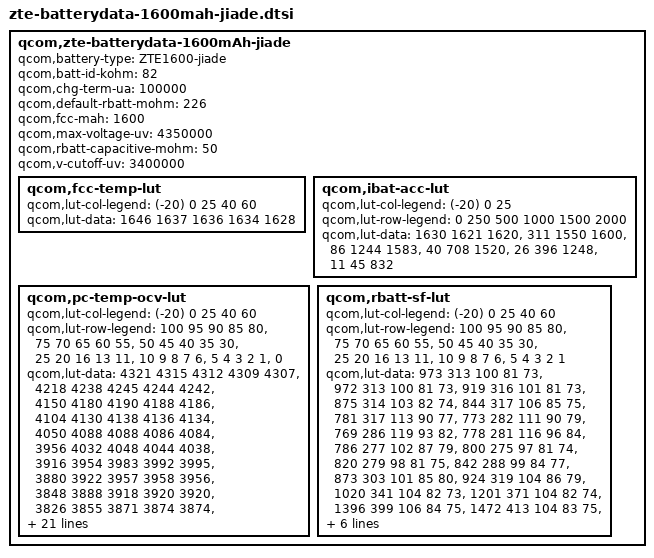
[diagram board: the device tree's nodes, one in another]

qcom,zte-batterydata-1600mAh-jiade {
	qcom,battery-type = "ZTE1600-jiade";
	qcom,batt-id-kohm = <82>;
	qcom,chg-term-ua = <100000>;
	qcom,default-rbatt-mohm = <226>;
	qcom,fcc-mah = <1600>;
	qcom,max-voltage-uv = <4350000>;
	qcom,rbatt-capacitive-mohm = <50>;
	qcom,v-cutoff-uv = <3400000>;

	qcom,fcc-temp-lut {
		qcom,lut-col-legend = <(-20) 0 25 40 60>;
		qcom,lut-data = <1646 1637 1636 1634 1628>;
	};

	qcom,ibat-acc-lut {
		qcom,lut-col-legend = <(-20) 0 25>;
		qcom,lut-row-legend = <0 250 500 1000 1500 2000>;
		qcom,lut-data = <1630 1621 1620>,
				<311 1550 1600>,
				<86 1244 1583>,
				<40 708 1520>,
				<26 396 1248>,
				<11 45 832>;
	};

	qcom,pc-temp-ocv-lut {
		qcom,lut-col-legend = <(-20) 0 25 40 60>;
		qcom,lut-row-legend = <100 95 90 85 80>,
					<75 70 65 60 55>,
					<50 45 40 35 30>,
					<25 20 16 13 11>,
					<10 9 8 7 6>,
					<5 4 3 2 1>,
					<0>;
		qcom,lut-data = <4321 4315 4312 4309 4307>,
				<4218 4238 4245 4244 4242>,
				<4150 4180 4190 4188 4186>,
				<4104 4130 4138 4136 4134>,
				<4050 4088 4088 4086 4084>,
				<3956 4032 4048 4044 4038>,
				<3916 3954 3983 3992 3995>,
				<3880 3922 3957 3958 3956>,
				<3848 3888 3918 3920 3920>,
				<3826 3855 3871 3874 3874>,
				<3808 3828 3838 3839 3839>,
				<3792 3806 3816 3817 3817>,
				<3780 3791 3798 3800 3798>,
				<3768 3780 3784 3784 3784>,
				<3754 3770 3772 3770 3766>,
				<3740 3758 3761 3752 3740>,
				<3724 3740 3743 3734 3720>,
				<3708 3724 3723 3714 3700>,
				<3694 3712 3702 3692 3680>,
				<3682 3704 3692 3683 3671>,
				<3674 3700 3690 3682 3670>,
				<3664 3697 3689 3681 3669>,
				<3654 3694 3688 3680 3668>,
				<3640 3690 3686 3678 3666>,
				<3624 3684 3682 3674 3660>,
				<3604 3670 3668 3656 3638>,
				<3576 3640 3631 3618 3600>,
				<3538 3594 3580 3565 3548>,
				<3478 3523 3512 3497 3480>,
				<3388 3424 3411 3400 3380>,
				<3200 3200 3200 3215 3200>;
	};

	qcom,rbatt-sf-lut {
		qcom,lut-col-legend = <(-20) 0 25 40 60>;
		qcom,lut-row-legend = <100 95 90 85 80>,
					<75 70 65 60 55>,
					<50 45 40 35 30>,
					<25 20 16 13 11>,
					<10 9 8 7 6>,
					<5 4 3 2 1>;
		qcom,lut-data = <973 313 100 81 73>,
				<972 313 100 81 73>,
				<919 316 101 81 73>,
				<875 314 103 82 74>,
				<844 317 106 85 75>,
				<781 317 113 90 77>,
				<773 282 111 90 79>,
				<769 286 119 93 82>,
				<778 281 116 96 84>,
				<786 277 102 87 79>,
				<800 275 97 81 74>,
				<820 279 98 81 75>,
				<842 288 99 84 77>,
				<873 303 101 85 80>,
				<924 319 104 86 79>,
				<1020 341 104 82 73>,
				<1201 371 104 82 74>,
				<1396 399 106 84 75>,
				<1472 413 104 83 75>,
				<1579 420 104 81 74>,
				<1692 434 105 83 75>,
				<1814 449 108 85 77>,
				<1963 470 111 87 78>,
				<2128 492 115 89 79>,
				<2333 513 119 90 80>,
				<2592 531 119 88 77>,
				<2917 551 117 88 78>,
				<3377 581 120 90 80>,
				<4138 632 128 95 81>,
				<5491 769 138 100 84>;
	};
};
